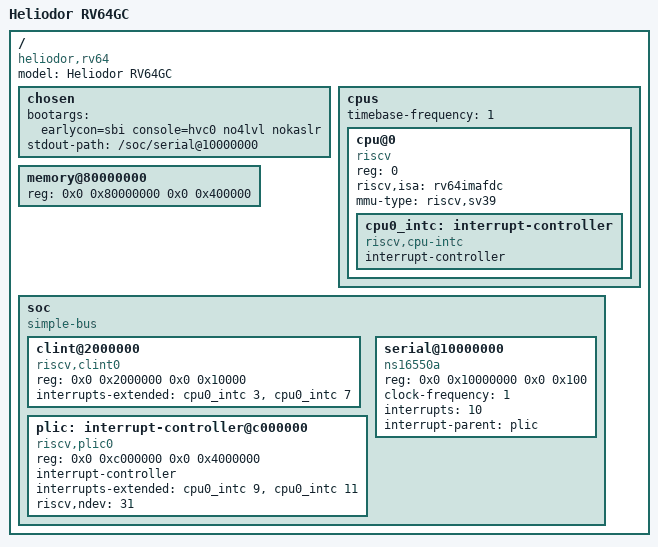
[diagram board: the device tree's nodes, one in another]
/dts-v1/;

/ {
	#address-cells = <2>;
	#size-cells = <2>;
	compatible = "heliodor,rv64";
	model = "Heliodor RV64GC";

	chosen {
		bootargs = "earlycon=sbi console=hvc0 no4lvl nokaslr";
		stdout-path = "/soc/serial@10000000";
	};

	cpus {
		#address-cells = <1>;
		#size-cells = <0>;
		timebase-frequency = <1>;

		cpu@0 {
			device_type = "cpu";
			compatible = "riscv";
			reg = <0>;
			riscv,isa = "rv64imafdc";
			mmu-type = "riscv,sv39";
			status = "okay";

			cpu0_intc: interrupt-controller {
				#interrupt-cells = <1>;
				compatible = "riscv,cpu-intc";
				interrupt-controller;
			};
		};
	};

	memory@80000000 {
		device_type = "memory";
		reg = <0x0 0x80000000 0x0 0x400000>;
	};

	soc {
		#address-cells = <2>;
		#size-cells = <2>;
		compatible = "simple-bus";
		ranges;

		clint@2000000 {
			compatible = "riscv,clint0";
			reg = <0x0 0x2000000 0x0 0x10000>;
			interrupts-extended = <&cpu0_intc 3>, <&cpu0_intc 7>;
		};

		plic: interrupt-controller@c000000 {
			compatible = "riscv,plic0";
			reg = <0x0 0xc000000 0x0 0x4000000>;
			#interrupt-cells = <1>;
			interrupt-controller;
			interrupts-extended = <&cpu0_intc 9>, <&cpu0_intc 11>;
			riscv,ndev = <31>;
		};

		serial@10000000 {
			compatible = "ns16550a";
			reg = <0x0 0x10000000 0x0 0x100>;
			clock-frequency = <1>;
			interrupts = <10>;
			interrupt-parent = <&plic>;
		};
	};
};
